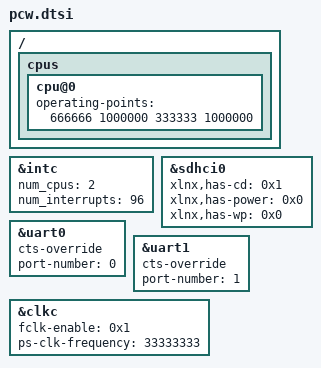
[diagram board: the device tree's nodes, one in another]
/*
 * CAUTION: This file is automatically generated by Xilinx.
 * Version:  
 * Today is: Mon Nov  2 12:04:15 2026
 */


/ {
	cpus {
		cpu@0 {
			operating-points = <666666 1000000 333333 1000000>;
		};
	};
};
&intc {
	num_cpus = <2>;
	num_interrupts = <96>;
};
&sdhci0 {
	status = "okay";
	xlnx,has-cd = <0x1>;
	xlnx,has-power = <0x0>;
	xlnx,has-wp = <0x0>;
};
&uart0 {
	cts-override ;
	device_type = "serial";
	port-number = <0>;
	status = "okay";
};
&uart1 {
	cts-override ;
	device_type = "serial";
	port-number = <1>;
	status = "okay";
};
&clkc {
	fclk-enable = <0x1>;
	ps-clk-frequency = <33333333>;
};
